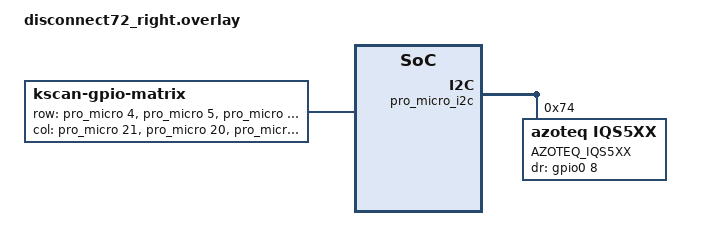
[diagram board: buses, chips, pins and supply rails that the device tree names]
#include "common.dtsi"

&default_transform { // The matrix transform for this board is 6 columns over because the left half is 6 columns wide according to the matrix.
    col-offset = <7>;
};

/{
    //chosen {
    //    zmk,mouse = &trackpad;
    //};

    kscan0: kscan {
        compatible = "zmk,kscan-gpio-matrix";
        label = "KSCAN";
        diode-direction = "col2row";

        row-gpios
            = <&pro_micro 4 (GPIO_ACTIVE_HIGH | GPIO_PULL_DOWN)> // Row 0 from the schematic file
            , <&pro_micro 5 (GPIO_ACTIVE_HIGH | GPIO_PULL_DOWN)> // Row 1 from the schematic file
            , <&pro_micro 6 (GPIO_ACTIVE_HIGH | GPIO_PULL_DOWN)> // Row 2 from the schematic file
            , <&pro_micro 7 (GPIO_ACTIVE_HIGH | GPIO_PULL_DOWN)> // Row 3 from the schematic file
            , <&pro_micro 8 (GPIO_ACTIVE_HIGH | GPIO_PULL_DOWN)> // Row 4 from the schematic file
            ;

        col-gpios
            = <&pro_micro 21 GPIO_ACTIVE_HIGH> // Col 0 in the schematic
            , <&pro_micro 20 GPIO_ACTIVE_HIGH> // Col 1 in the schematic
            , <&pro_micro 19 GPIO_ACTIVE_HIGH> // Col 2 in the schematic
            , <&pro_micro 15 GPIO_ACTIVE_HIGH> // Col 3 in the schematic
            , <&pro_micro 18 GPIO_ACTIVE_HIGH> // Col 4 in the schematic
            , <&pro_micro 14 GPIO_ACTIVE_HIGH> // Col 5 in the schematic
            ;
    };
//    right_encoder: encoder_right {
//        compatible = "alps,ec11";
//        label = "RIGHT_ENCODER";
//        a-gpios = < &pro_micro 10 (GPIO_ACTIVE_HIGH | GPIO_PULL_UP)>;
//        b-gpios = < &pro_micro 16 (GPIO_ACTIVE_HIGH | GPIO_PULL_UP)>;
//        resolution = <4>;
//    };

    //sensors {
    //    compatible = "zmk,keymap-sensors";
        // sensors = <&right_encoder>, ;
        //sensors = <&trackpad>;
    //};
};

//&right_encoder {
//    status = "okay";
//};

&pro_micro_i2c {
	status = "okay";

    trackpad: trackpad@74 {
        compatible = "azoteq,iqs5xx";
        label = "AZOTEQ_IQS5XX";
        status = "okay";
        reg = <0x74>;
        dr-gpios = <&gpio0 8 GPIO_ACTIVE_HIGH>;
	};
};
